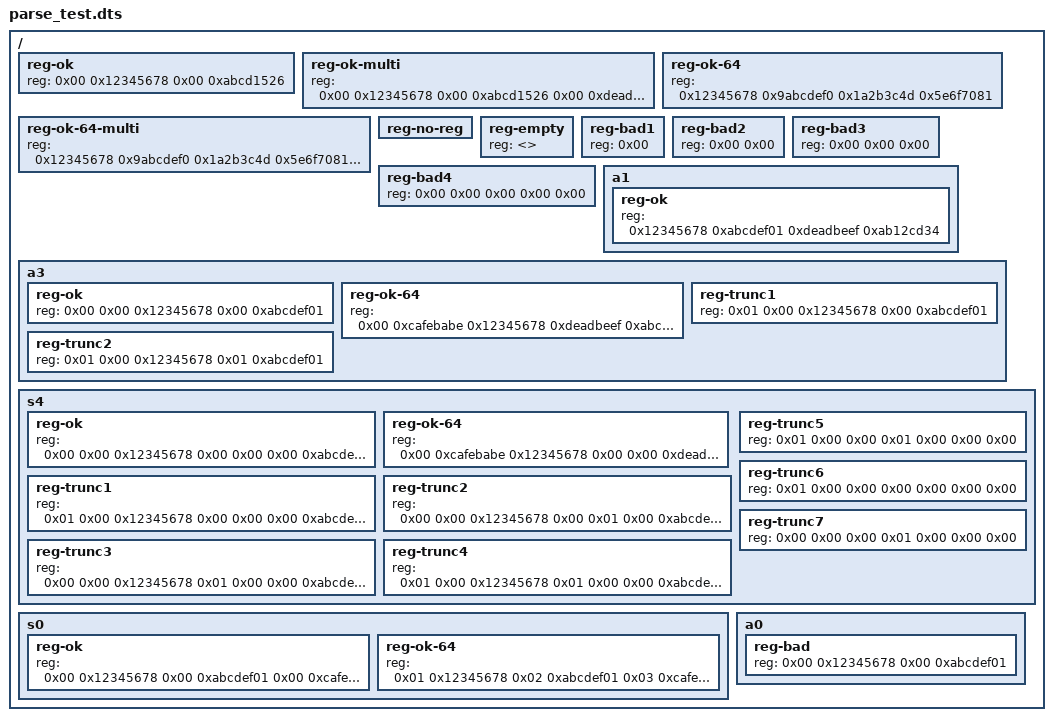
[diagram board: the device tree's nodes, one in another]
// Copyright 2023 Andrew Oates.  All Rights Reserved.
//
// Licensed under the Apache License, Version 2.0 (the "License");
// you may not use this file except in compliance with the License.
// You may obtain a copy of the License at
//
//     http://www.apache.org/licenses/LICENSE-2.0
//
// Unless required by applicable law or agreed to in writing, software
// distributed under the License is distributed on an "AS IS" BASIS,
// WITHOUT WARRANTIES OR CONDITIONS OF ANY KIND, either express or implied.
// See the License for the specific language governing permissions and
// limitations under the License.

/dts-v1/;

/ {
  #address-cells = <0x02>;
  #size-cells = <0x02>;

  reg-ok {
    reg = <0x00 0x12345678 0x00 0xabcd1526>;
  };

  reg-ok-multi {
    reg = <0x00 0x12345678 0x00 0xabcd1526
           0x00 0xdeadbeef 0x00 0x12345678>;
  };

  reg-ok-64 {
    reg = <0x12345678 0x9abcdef0 0x1a2b3c4d 0x5e6f7081>;
  };

  reg-ok-64-multi {
    reg = <0x12345678 0x9abcdef0 0x1a2b3c4d 0x5e6f7081
           0xdeadbeef 0x12345678 0xabcdef01 0x1234abcd>;
  };

  reg-no-reg {
  };

  reg-empty {
    reg = <>;
  };

  reg-bad1 {
    reg = <0x00>;
  };

  reg-bad2 {
    reg = <0x00 0x00>;
  };

  reg-bad3 {
    reg = <0x00 0x00 0x00>;
  };

  reg-bad4 {
    reg = <0x00 0x00 0x00 0x00 0x00>;
  };

  a1 {
    #address-cells = <0x01>;
    #size-cells = <0x01>;

    reg-ok {
      reg = <0x12345678 0xabcdef01 0xdeadbeef 0xab12cd34>;
    };
  };

  a3 {
    #address-cells = <0x03>;
    #size-cells = <0x02>;

    reg-ok {
      reg = <0x00 0x00 0x12345678 0x00 0xabcdef01>;
    };

    reg-ok-64 {
      reg = <0x00 0xcafebabe 0x12345678 0xdeadbeef 0xabcdef01>;
    };

    reg-trunc1 {
      reg = <0x01 0x00 0x12345678 0x00 0xabcdef01>;
    };

    reg-trunc2 {
      reg = <0x01 0x00 0x12345678 0x01 0xabcdef01>;
    };
  };

  s4 {
    #address-cells = <0x03>;
    #size-cells = <0x04>;

    reg-ok {
      reg = <0x00 0x00 0x12345678 0x00 0x00 0x00 0xabcdef01>;
    };

    reg-ok-64 {
      reg = <0x00 0xcafebabe 0x12345678 0x00 0x00 0xdeadbeef 0xabcdef01>;
    };

    reg-trunc1 {
      reg = <0x01 0x00 0x12345678 0x00 0x00 0x00 0xabcdef01>;
    };

    reg-trunc2 {
      reg = <0x00 0x00 0x12345678 0x00 0x01 0x00 0xabcdef01>;
    };

    reg-trunc3 {
      reg = <0x00 0x00 0x12345678 0x01 0x00 0x00 0xabcdef01>;
    };

    reg-trunc4 {
      reg = <0x01 0x00 0x12345678 0x01 0x00 0x00 0xabcdef01>;
    };

    reg-trunc5 {
      reg = <0x01 0x00 0x00 0x01 0x00 0x00 0x00>;
    };

    reg-trunc6 {
      reg = <0x01 0x00 0x00 0x00 0x00 0x00 0x00>;
    };

    reg-trunc7 {
      reg = <0x00 0x00 0x00 0x01 0x00 0x00 0x00>;
    };

  };

  s0 {
    #address-cells = <0x02>;
    #size-cells = <0x0>;

    reg-ok {
      reg = <0x00 0x12345678 0x00 0xabcdef01 0x00 0xcafebabe>;
    };

    reg-ok-64 {
      reg = <0x01 0x12345678 0x02 0xabcdef01 0x03 0xcafebabe>;
    };
  };

  a0 {
    #address-cells = <0x0>;
    #size-cells = <0x2>;

    reg-bad {
      reg = <0x00 0x12345678 0x00 0xabcdef01>;
    };
  };
};
